# RL6955_IP_SVD register map
Vendor: Realtek
Registers are 32-bit, read-write, reset 0x0 unless marked. A register's access mark holds for its fields unless they carry their own. Offsets are from the block's base; [hi:lo] are bit positions; {n}, {i} and the like mark numbered series; <NAME> marks a mode.

## RMII_REG
Base 0x41800000
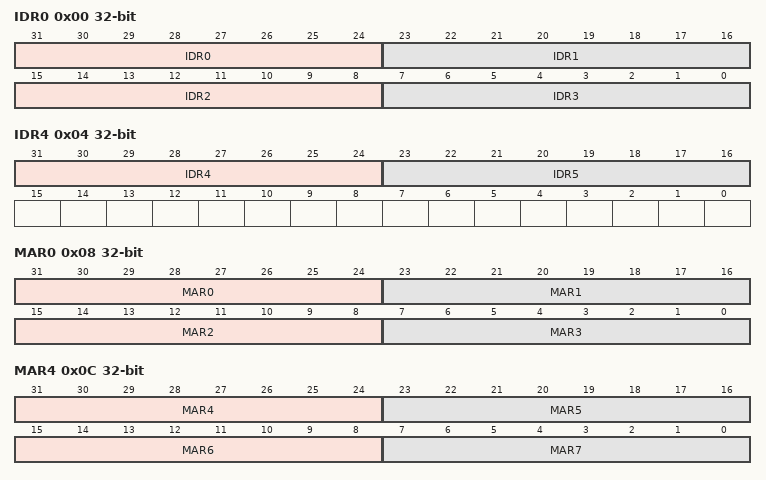
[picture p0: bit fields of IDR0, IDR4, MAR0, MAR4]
0x00 IDR0
  [31:24] IDR0 — The ID register0-5 are only permitted to write by 4-byte access. Read access can be byte, word, or double word access.
  [23:16] IDR1
  [15:8] IDR2
  [7:0] IDR3
0x04 IDR4
  [31:24] IDR4, [23:16] IDR5
0x08 MAR0
  [31:24] MAR0 — Multicast Register 0, The MAR register0-7 are only permitted to write by 4-byte access. Read access can be byte, word, or double word access. Driver is responsible for initializing these registers. The MAR7-0 define 64 bits which is a bit wise index of the multicast function of multicast addresses. The hash function of multicast address is the upper 6 MSB's of the CRC32 of the address (destination). The index then is the numerical representation of those 6 bits in hex format.
  [23:16] MAR1 — Multicast Register 1
  [15:8] MAR2 — Multicast Register 2
  [7:0] MAR3 — Multicast Register 3
0x0C MAR4
  [31:24] MAR4 — Multicast Register 4
  [23:16] MAR5 — Multicast Register 5
  [15:8] MAR6
  [7:0] MAR7 — Multicast Register 7
0x10 TxOKCNT 16-bit ro
  [15:0] TxOK — 16-bit counter of Tx Ok packets. Rolls over automatically. Write to clear.
0x12 RxOKCNT 16-bit ro
  [15:0] RxOk — 16-bit counter of Rx Ok packets. Rolls over automatically. Write to clear.
0x14 TxErr 16-bit ro
  [15:0] TxErr — 16-bit counter of TxErr packets. Rolls over automatically. Write to clear. The source of TxErr are txunder, txabt(in half-duplex mode) or txlinkerr.
0x16 RxErr 16-bit ro
  [15:0] RxErr — 16-bit counter of RxErr packets. Rolls over automatically. Write to clear. The source of RxErr are GMAC meets the following condition when rx fifo is not full.: 1. RCR.accept runt = 0, but the ingress pkt length < 64B. 2. RCR.accepterr = 0, but the ingress pkt is a CRC error pkt.
0x18 MissPkt 16-bit ro
  [15:0] MissPkt — 16-bit counter of Missed packets. Rolls over automatically. Write to clear.
0x1A FAE 16-bit ro
  [15:0] FAE — 16-bit counter of FAE (Frame Alignment Error) packets. Rolls over automatically. Write to clear. RCR.AER should be high. When FAE occurs in 10/100mode, the following thins happens: *Rx status des.CRC error does not assert if the ingress(exclude alignment error nibble) if correct. *RxErr_reg increased by 1. *FAE_reg increased by 1 *Rx status des.RCDF does not asserts. data length does not include alignment error nibble.
0x1C Tx1Col 16-bit ro
  [15:0] Tx1Col — 16-bit counter of TxCol packets. Rolls over automatically. Write to clear. This only record which have entered just one collision before Tx OK
0x1E TxMCol 16-bit ro
  [15:0] TxMCol — 16-bit counter of TxCol packets. Rolls over automatically. Write to clear. This keeps track of those packets with less than 16 collisions (or the configured retry count) before Tx Ok
0x20 RxOkPhy 16-bit ro
  [15:0] RxOkPhy — 16-bit counter of Rx Ok packets with physical address matching destination address. Rolls over automatically. Write to clear.
0x22 RxOkBrd 16-bit ro
  [15:0] RxOkBrd — 16-bit counter of Rx Ok packets with broadcast destination address.. Rolls over automatically. Write to clear.
0x24 RxOkMu1 16-bit ro
  [15:0] RxOkMul — 16-bit counter of Rx Ok packets with multicast destination address. Rolls over automatically. Write to clear.
0x26 TxAbt 16-bit ro
  [15:0] TxAbt — 16-bit counter of Tx aborted packets. Rolls over automatically. Write to clear. This accounts for over collision, underrun, LNK failure conditions.
0x28 TXUNDERC 16-bit ro
  [15:0] TXUNDERC — 16-bit counter of Tx Underrun packets. Rolls over automatically. Write to clear. gmac only.
0x2A Misspkt_rdu 16-bit ro
  [15:0] RDU_MISSPKTC — 16-bit counter of miss packets due to rx descriptor is unavailable. Rolls over automatically. Write to clear. gmac only.
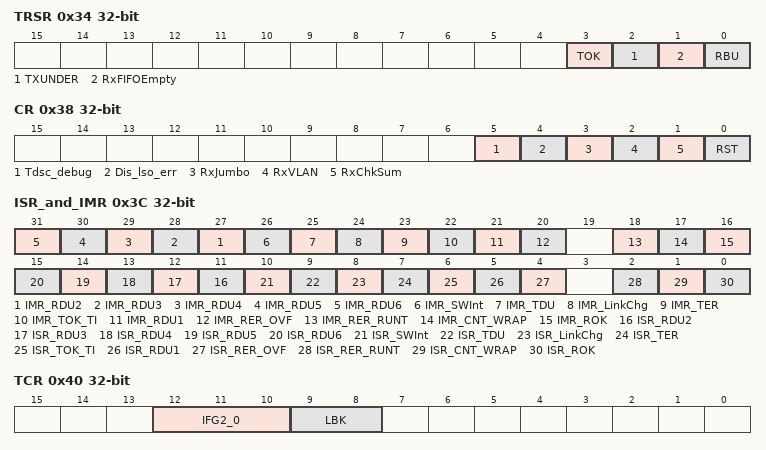
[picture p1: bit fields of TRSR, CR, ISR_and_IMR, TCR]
0x34 TRSR ro
  [3] TOK — Transmit OK: Set to 1 indicates that the transmission of a packet was completed successfully and no transmit underrun occurs.
  [2] TXUNDER — Transmit FIFO Underrun: Set to 1 if the Tx FIFO was exhausted during the transmission of a packet.
  [1] RxFIFOEmpty — Rx Fifo is Empty.
  [0] RBU — Rx buff is un-available, rx full
0x38 CR access per field
  [5] Tdsc_debug rw — Tx descriptor debug
  [4] Dis_lso_err rw — Disable LSO error
  [3] RxJumbo rw — 1: support jumbo packet receiving. The maximum packet size is 16384B(0x4000). 0: Does not support jumbo packet receiving. When rxjumbo sets to 1, the minium rx descriptor ring size is 16.
  [2] RxVLAN rw — Receive VLAN de-tagging enable.1: Enable. 0: Disable. 1: detag vlan and set rx status dsc.tava = 1 when ingress packet has vlantag. 0: disable detag vlan and rx status dsc.tava = 0.
  [1] RxChkSum rw — Receive checksum offload enable. 1: Enable. 0: Disable.
  [0] RST wo — Reset: Setting to 1 forces the Ethernet module to a software reset state which disables the transmitter and receiver, reinitializes the FIFOs, triggers interrupt Swint for RISC to reset the system buffer pointer to the initial value Tx/Rx FDP. The values of IDR0-5 and MAR0-7 will have no changes. This bit is 1 during the reset operation, and is cleared to 0 by the Ethernet Module when the reset operation is complete.
0x3C ISR_and_IMR access per field
  [n+25] IMR_RDU{n} rw (n=2..6)
  [26] IMR_SWInt rw
  [25] IMR_TDU rw
  [24] IMR_LinkChg rw
  [23] IMR_TER rw
  [22] IMR_TOK_TI rw
  [21] IMR_RDU1 rw
  [20] IMR_RER_OVF rw
  [18] IMR_RER_RUNT rw
  [17] IMR_CNT_WRAP rw
  [16] IMR_ROK rw
  [n+9] ISR_RDU{n} ro (n=2..6) — Rx Descriptor Unavailable for RING{n}: When set, indicates Rx descriptor is unavailable. Write 1 to clear.
  [10] ISR_SWInt ro — Software Interrupt pending: When set to 1 indicates a software interrupt was forced. Write 1 to clear.
  [9] ISR_TDU ro — Tx Descriptor Unavailable: When set, indicates Tx descriptor is unavailable. Write 1 to clear.
  [8] ISR_LinkChg ro — Link Change: Write 1 to clear.
  [7] ISR_TER ro — Transmit (Tx) Error: Indicates that a packet transmission was aborted, due to excessive collisions, according to the TXRR's setting. Write 1 to clear.
  [6] ISR_TOK_TI ro — Transmit Interrupt: Indicates that the DMA of the last descriptor of TxIntMitigation number of Tx packet has completed and the last descriptor has been closed. Write 1 to clear.
  [5] ISR_RDU1 ro — Rx Descriptor Unavailable for RING1: When set, indicates Rx descriptor is unavailable. Write 1 to clear.
  [4] ISR_RER_OVF ro — Rx FIFO Overflow, caused by RBO/RDU, poor system bus (Lexra bus) performance, or overloaded Lexra bus traffic. Write 1 to clear.
  [2] ISR_RER_RUNT ro — Rx error caused by runt error characterized by the frame length in bytes being less than 64 bytes. Write 1 to clear.
  [1] ISR_CNT_WRAP ro — Tx/rx counter wrap interrupt.
  [0] ISR_ROK ro — Receive (Rx) OK: This interrupt is set either when RxIntMitigation packet is met or RxPktTimer expires. Write 1 to clear.
0x40 TCR
  [12:10] IFG2_0 — InterFrameGap Time: This field allows the user to adjust the interframe gap time longer than the standard: 9.6 us for 10Mbps, 960 ns for 100Mbps. The time can be programmed from 9.6 us to 14.4 us (10Mbps) and 960ns to 1440ns (100Mbps). The formula for the inter frame gap is: IFG[2:0] IFG@1000MHz (nS) IFG@100MHz (nS) IFG@10MHz (uS) 0 1 1 96 960 9.6 1 0 0 96 +8 * 1 960 +8 * 10 9.6 +8 * 0.1 1 0 1 96 + 16 * 1 960 + 16 * 10 9.6 + 16 * 0.1 1 1 0 96 + 24 * 1 960 + 24 * 10 9.6 + 24 * 0.1 1 1 1 96 + 32 * 1 960 + 32 * 10 9.6 + 32 * 0.1 0 0 0 96 + 40 * 1 960 + 40 * 10 9.6 + 40 * 0.1 0 0 1 96 + 48 * 1 960 + 48 * 10 9.6 + 48 * 0.1 0 1 0 96 + 96 * 1 960 + 96 * 01 9.6 + 96 * 0.1
  [9:8] LBK — The loopback function must be independent of the link state. 2'b00 : normal operation 2'b01 : Loopback mode_R2T(lbkmode_r2t) : Lbk methld: no SW requirement. 1. receive ingress data. 2. assign rxd to txd (txd). 3. egress pkt. b10 : Reserved 2'b11 : Loopback mode(lbk_mode). Lbk method: 1. rx fet descriptor. 2. tx fet descriptor and data 3. put data in txfifo 4. assign txd to rxd.(lbk) 5. gmac mv data to lxb. In this mode(lbk_mode), the recommended value of RC_REG(0x44) is 0xf.
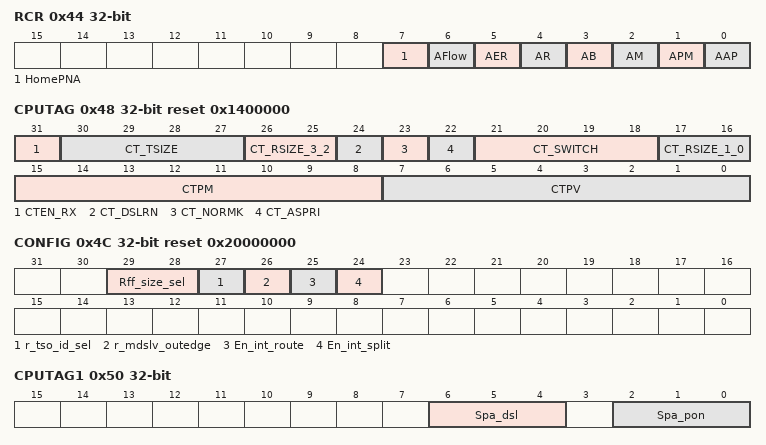
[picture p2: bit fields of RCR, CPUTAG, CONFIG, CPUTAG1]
0x44 RCR
  [7] HomePNA — Home PNA mode
  [6] AFlow — Accept flow control : When set to 1, flow control packet will also be received & DMA to rx buffer for debug. Default is 0.
  [5] AER — Accept Error Packet: When set to 1, all packets with CRC error, alignment error, and/or collided fragments will be accepted. Rxerrc keeps, Rxokc +1, Rx status dsc.CRC =1, Rx status dsc.RCDF =0. When set to 0, all packets with CRC error, alignment error, and/or collided fragments will be rejected. Rxerrc +1, Rxokc keeps, Rx status dsc.CRC =0, Rx status dsc.RCDF =1.
  [4] AR — Accept Runt: This bit allows the receiver to accept packets that are smaller than 64 bytes. The packet must be at least 8 bytes long to be accepted as a runt. Set to 1 to accept runt packets.
  [3] AB — Set to 1 to accept broadcast packets, 0 to reject.
  [2] AM — Set to 1 to accept multicast packets, 0 to reject. RC_REG.AB and AM should be enabled simulatanously.
  [1] APM — Set to 1 to accept physical match packets, 0 to reject.
  [0] AAP — Set to 1 to accept all packets with physical destination address, 0 to reject.
0x48 CPUTAG reset 0x1400000
  [31] CTEN_RX — Enable parsing ingress packet with cputag format.
  [30:27] CT_TSIZE — Cputag size in egress pkt. CTT_size: 4'h0: 0 Byte 4'h1: 4 Byte 4'h2: 8Byte 4'h3: 12 Byte
  [26:25] CT_RSIZE_3_2 — After rl8681 (including), this field is only for ingress pkt. CTR_size: 4'h0: 0 Byte 4'h1: 4 Byte 4'h2: 8Byte F or Apollo cputag with PTP timestamp, set CT_RSIZE to h2.
  [24] CT_DSLRN — In rtl8370s, Setting of Disable Learning field in tx cputag. Setting of Disable Learning field in RTL8368 or DSLRN field in RTL8307h tx cputag when short_dsc_format = 0.
  [23] CT_NORMK — Setting of NORMK field in RTL8307h tx cputag when short_dsc_format = 0.
  [22] CT_ASPRI — In RTL8307h, setting ASPRI field in tx cputag when short_dsc_format = 0. In RTL8370S, setting priority select field in tx cputag when short_dsc_format =0..
  [21:18] CT_SWITCH — Support cputag format of switch 0: no cputag support 1: 8368 2: 8306 3: 8307 4: 8370 5: gmac in 8681. 6: gmac in Apollo, rle0371, rl6266 and rtl9601(rle0639)
  [17:16] CT_RSIZE_1_0
  [15:8] CTPM — CPU tag protocol mask. 8306:0xf0 8368:0xe0 8370:0xff 8307h:0xff
  [7:0] CTPV — CPU tag protocol value. 8306:0x90 8368:0xa0 or 0xb0 8370:0x04 8307h:0x04
0x4C CONFIG reset 0x20000000
  [29:28] Rff_size_sel — Set gmac_rxfifo size. 2'b00: 1KB 2'b01: 1664B 2'b10: 2KB
  [27] r_tso_id_sel — 0: each ID of IP header is same as original ID. 1: increment 1 from original ID. Default value is 0.
  [26] r_mdslv_outedge — this bit works only in phy_mode 0: change mdio output data in falling edge 1: change mdio output data in rising edge
  [25] En_int_route — 0: disable interrupt routing, IMR0_reg, IMR1_reg. 1: enable interrupt routing, IMR0_reg, IMR1_reg.
  [24] En_int_split — When, en_int_route = 0, 0: only int.tdu, tok and rok present. 1: IMR0_reg, IMR1_reg and ISR1_reg present. When en_int_route = 1, this field is 1.
0x50 CPUTAG1
  [6:4] Spa_dsl
  [2:0] Spa_pon — The ingress cputag.SPA=PON field. Used in Apollo cputag.
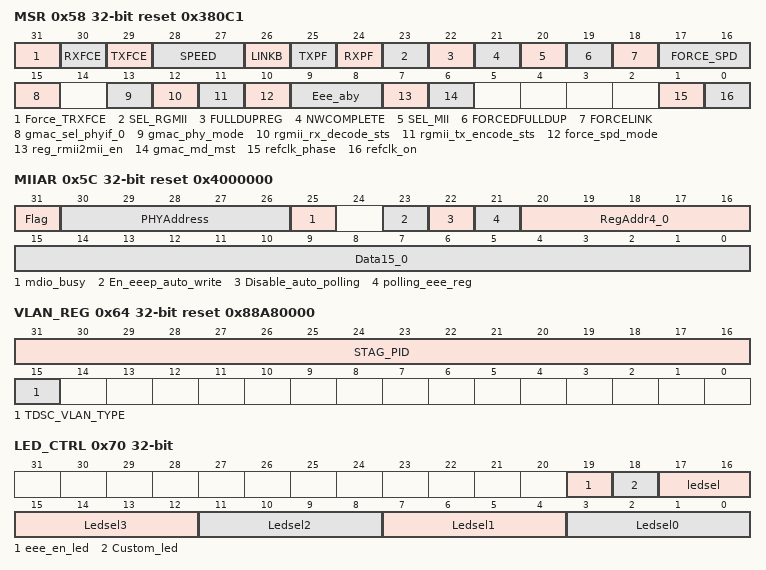
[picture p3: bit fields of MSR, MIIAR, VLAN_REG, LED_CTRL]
0x58 MSR access per field reset 0x380C1
  [31] Force_TRXFCE rw — Force Tx/RX Flow Control: 1 = enabled Flow control in the absence of NWAY. 0 = disables Flow control in the absence of NWAY. Version effect: rl6166(ECO) and after.
  [30] RXFCE rw — RX Flow control Enable: The flow control is enabled in full-duplex mode only. Packets are dropped if buffer is exhausted. Default is 0. 1 = Rx Flow Control Enabled. 0 = Rx Flow Control Disabled.
  [29] TXFCE rw — Tx Flow Control Enable: 1 = tx flow control enabled. 0 = tx flow control disabled. ACCEPT ERROR MUST NOT BE ENABLED
  [28:27] SPEED ro — {SPEED_1000, SPEED_10} 00: 100Mbps, 01: 10Mbps 10: 1000Mbps, 11: not allowed
  [26] LINKB ro — Inverse of Link status. 0 = Link OK. 1 = Link Fail.
  [25] TXPF ro — Tx Pause frame: 1 = Ethernet module has sent a pause packet. 0 = the Ethernet module has sent a timer done packet.
  [24] RXPF ro — Pause Flag: 1 = Ethernet module is in backoff state because a pause packet received. 0 = pause state is clear.
  [23] SEL_RGMII rw — gmac_sel_rgmii
  [22] FULLDUPREG ro — Indicates Full duplex mode from mdio results.
  [21] NWCOMPLETE ro — Nway complete
  [20] SEL_MII ro — indicates in mii mode.
  [19] FORCEDFULLDUP rw — force gmac operates at full duplex mode. This bit is Write only in RLE0315. This bit is R/W in RLE0390 (原RL6166). 1'b1: force gmac in full duplex mode. 1'b0: duplex status is from MDIO auto-polling. Not means gmac is in half duplex mode.
  [18] FORCELINK rw — force gmac in link ok mode. This bit is Write only in RLE0315. This bit is R/W in RLE0390 (RL6166). 1'b1: force gmac in linkok. 1'b0: link status is from MDIO auto-polling.
  [17:16] FORCE_SPD rw — Force gmac in 10/100/GIGA mode. 2'b00: 100M 2'b01: 10M 2'b10: GIGA 2'b11: not force mode. These bits are Write only in RLE0390 (RL6166). The current speed status of gmac can be checked in MSR_reg.{speed1000, speed_10}. In force mode, SW can set gmac operates in , FD and Link ok(for example) and SW can not set gmac operates in , HD and Link ok. When FORCEDFULLDUP is b0, the duplex status is from MDIO auto-polling, therefore, it is not controlled by SW.
  [15] gmac_sel_phyif_0 ro — 1: phy interface 0.works. 0: phy interface 1 works.
  [13] gmac_phy_mode rw — 1: in phy mode. (bit[6] will be read as '0') 0: not in phy mode. (bit[6] will be read as '1')
  [12] rgmii_rx_decode_sts rw — 0: Does not support rgmii in band status(link status, speed and duplex mode of the PHY) by decoding rxd. 1: Supports rgmii in band status(link status, speed and duplex mode of the PHY) by decoding rxd.
  [11] rgmii_tx_encode_sts rw — This field is valid only in phy mode. 0: Does not support rgmii in band status(link status, speed and duplex mode of the PHY) by encoding txd. 1: Supports rgmii in band status(link status, speed and duplex mode of the PHY) by encoding txd.
  [10] force_spd_mode rw — 1: gmac is in force speed mode. The real speed in force mode is set in MS_REG.FORCE_SPD. 0: gmac speed status is from md operation.
  [9:8] Eee_aby ro — Indicates eee ability of PCS. Eee_aby[0]: eee ability in 100M Eee_aby[1]: eee ability in giga mode.
  [7] reg_rmii2mii_en rw — 1: transfer MII signals to RMII signals This function is only valid in MII mode. (default 0: for AmebaI//AmebaPro/AmebaPro2)
  [6] gmac_md_mst ro — 1: GMAC is used to be MDIO master. (When bit[13] is setting as '0') 0: GMAC is used to be MDIO slave. (When bit[13] is setting as '1')
  [1] refclk_phase rw — 1: for Tx transaction, TXEN & TXD signals are changed on the falling edge of REF_CLK; for Rx transaction, RXD signals are sampled on the falling edge of REF_CLK 0: for Tx transaction, TXEN & TXD signals are changed on the rising edge of REF_CLK; for Rx transaction, RXD signals are sampled on the rising edge of REF_CLK
  [0] refclk_on rw — 1: REF_CLK on 0: REF_CLK off
0x5C MIIAR access per field reset 0x4000000
  [31] Flag rw — Flag bit, used to identify access to MII register: 1: Write data to MII register. Turns to 0 automatically upon completion of MAC writing to the specified MII register. 0: Read data from MII register. Turns to 1 automatically upon completion of MAC reading the specified MII register. Read write turn around time I s about 64 us.
  [30:26] PHYAddress rw — Defines the Phy address for the MII.
  [25] mdio_busy ro — MDIO is busy
  [23] En_eeep_auto_write rw — HW auto writes PCS.page4.reg20 and reg27 to adjust analog parameters based on eeep_lpi state. SW should change page to page4 then set MIIA_REG.en_eeep_auto_write. HW will write eeep_abig_on/off and eeep_ldvbias_on/off (in EEEP_CR6_REG and EEEP_CR7_REG) to PCS.page4.reg20 and reg27, respectively, based on eeep_lpi state. If SW wants to access another page of PCS, SW should disable MIIA_REG.en_eeep_auto_write.
  [22] Disable_auto_polling rw — Disable auto polling feature of mdio operation. 0: HW auto polling PCS status. 1: HW does not auto polling PCS status.
  [21] polling_eee_reg rw — polling PCS EEE advertisement register (7.60). In rl6166(原rle0315) and before: this bit is not supported. In rle0390: In in-direct method, gmac had to access PCS register by multiples R/W of reg13 and 14. It is OK for PCS to be aborted in the middle of indirect method. In rle0371: HW will complete current indirect access to PCS then stop in-direct method. Please refer to EEE_CR1_reg.
  [20:16] RegAddr4_0 rw — Defines 5-bit MII register address.
  [15:0] Data15_0 rw — Defines 16 bit MII resgister data.
0x60 SWINT wo
  [24] SWINT — Write 1 will force ISR register bit 10 set to 1
0x64 VLAN_REG reset 0x88A80000
  [31:16] STAG_PID — Set the s-tag protocol identifier. This field is valid only when COM_REG.TDSC_VLAN_TYPE is high.
  [15] TDSC_VLAN_TYPE — 1: tx command descriptor.tx_vlan_action is for s-tag. 0: tx command descriptor.tx_vlan_action is for c-tag.
0x70 LED_CTRL
  [19] eee_en_led — Enable/disable lpi led.
  [18] Custom_led — Custom led mode. 1: using custom led matrix table. 0: using Non-custom led table.
  [17:16] ledsel — Non custom led select. Following EEE spec, combine the Link signal and LPI signal in the same LED pin. While entering LPI state, LED will blink with 2784ms cycle, of which the first 2349ms LED light is turned off, after 435ms is turned on. NO EEE in RL6166.
  [4n+3:4n] Ledsel{n} (n=0..3) — Custom led{n} select.
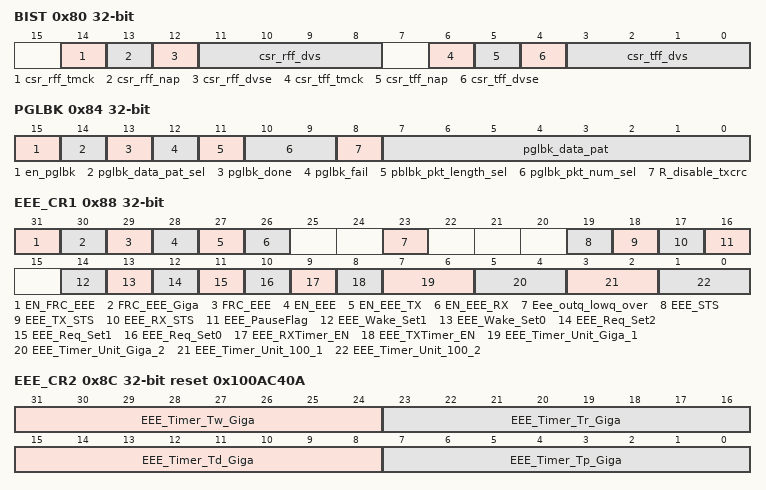
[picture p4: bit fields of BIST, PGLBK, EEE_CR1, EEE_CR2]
0x80 BIST
  [14] csr_rff_tmck — Set TMCK for RXFIFO
  [13] csr_rff_nap — Set NAP for RXFIFO
  [12] csr_rff_dvse — Set DVSE for RXFIFO
  [11:8] csr_rff_dvs — Set DVS for RXFIFO
  [6] csr_tff_tmck — Set TMCK for TXFIFO
  [5] csr_tff_nap — Set NAP for TXFIFO
  [4] csr_tff_dvse — Set DVSE for TXFIFO
  [3:0] csr_tff_dvs — Set DVS for TXFIFO
0x84 PGLBK access per field
  [15] en_pglbk rw — Enable packet generator mode
  [14] pglbk_data_pat_sel rw — 1: fixed pattern, 0: pseudo random
  [13] pglbk_done ro — packet generator in wire lbk mode status. 1: done
  [12] pglbk_fail ro — packet generator in wire lbk mode status. 1: fail
  [11] pblbk_pkt_length_sel rw — 0: random (range: 64-1504B), 1: 64B
  [10:9] pglbk_pkt_num_sel rw — 2'b00: 100 pkts, 2'b10: 5 pkts. 2'b01: 1 pkt 2'b11: reserved.
  [8] R_disable_txcrc rw — 1: not append CRC for egress packet. 0: append CRC for egress packet.
  [7:0] pglbk_data_pat rw — Pattern inside tx packet when pglbk_data_pat_sel is high. For RLE0516, only pglbk_data_pat[3:0] are used.
0x88 EEE_CR1 access per field
  [31] EN_FRC_EEE rw — Enable EEE force mode 0: Disable EEE FORCE Mode 1: Enable EEE FORCE Mode If EN_FRC_EEE=1, both FRC_EEE_Giga and FRC_EEE_100 are used to force MAC operation ability.
  [30] FRC_EEE_Giga rw — If EN_FRC_EEE=1, FRC_EEE_Giga: 0: Disable MAC EEE ability for 1000BASE-T. 1: Enable MAC EEE ability for 1000BASE-T. If EN_FRC_EEE=0, FRC_EEE_Giga means EEE advertisement register 7.60 bit[2]
  [29] FRC_EEE rw — If EN_FRC_EEE=1, FRC_EEE_100 0: Disable MAC EEE ability for 100BASE-TX. 1: Enable MAC EEE ability for 100BASE-TX. If EN_FRC_EEE=0, FRC_EEE_100 means EEE advertisement register 7.60 bit[1]
  [28] EN_EEE rw — Set same as PHY setting, for LED.
  [27] EN_EEE_TX rw — Enable MAC TX EEE ability 0: Disable EEE ability for TX. 1: Enable EEE ability for TX.
  [26] EN_EEE_RX rw — Enable MAC RX EEE ability 0: Disable EEE ability for RX. 1: Enable EEE ability for RX. Application note : The following methods could be used to disable EEE function. a) n[1:0] = 00 -> completely disable EEE function, or b) n[3:2] = 00 -> disable /1000Mbps EEE capability (excludes 10Mbps ).
  [23] Eee_outq_lowq_over rw — SW has many packets to be tranmitted, then set this bit to tell HW leave lpi state in condition2.
  [19] EEE_STS ro — Indicate EEE status, both TX and RX. 1: Both TX and RX in LPI mode simultaneously. 0: not both TX and RX in LPI mode simultaneously
  [18] EEE_TX_STS ro — Indicate EEE TX status 1: TX is in LPI mode. 0: TX is in normal mode.
  [17] EEE_RX_STS ro — Indicate Port 0 EEE RX status 1: RX is in LPI mode. 0: RX is in normal mode.
  [16] EEE_PauseFlag ro — Set indication for LPI request due to RX pause on frame. 1: indicate RX pause on frame; 0: no indicate.
  [14] EEE_Wake_Set1 rw — Enable LPI TX high priority pkt Wakeup decision maker for EEE. 1: enable; 0: disable. Gmac will leave lpi mode when EEE_CR1_reg.txq_th is met or one of the egress is larger than 512B.
  [13] EEE_Wake_Set0 rw — Enable LPI TX transmit wakeup decision maker for EEE. 1: enable; 0: disable.
  [12] EEE_Req_Set2 rw — Enable LPI TX request RX pause on frame decision maker for EEE. 1: enable; 0: disable.
  [11] EEE_Req_Set1 rw — Enable LPI TX request queue empty decision maker for EEE. 1: enable; 0: disable. For RLE0390(原RL6166), only for tx is single descriptor operation. For next version, this bit can support multi-descriptor operation.
  [10] EEE_Req_Set0 rw — Enable LPI TX request Rate decision maker for EEE. 1: enable; 0: disable.
  [9] EEE_RXTimer_EN rw — Enable RX meter to count RX LPI status time
  [8] EEE_TXTimer_EN rw — Enable TX meter to count TX LPI status time
  [7:6] EEE_Timer_Unit_Giga_1 rw — Set the unit for timer T_wakeup, T_tx_rate, and T_pause in EEE function. 00: 1uS; 01: 16 uS; 10: 128 uS; 11: 1024uS.
  [5:4] EEE_Timer_Unit_Giga_2 rw — Set the unit for timer T_tx_delay in EEE function. 00: 8uS; 01: 64uS; 10: 256uS; 11: 1024uS.
  [3:2] EEE_Timer_Unit_100_1 rw — Set the unit for timer T_wakeup, T_tx_rate, and T_pause in EEE function. 00: 1uS; 01: 16uS; 10: 128uS; 11: 1024uS.
  [1:0] EEE_Timer_Unit_100_2 rw — Set the unit for timer T_tx_delay in EEE function. 00: 8uS; 01: 64uS; 10: 512uS; 11: 1024uS.
0x8C EEE_CR2 reset 0x100AC40A
  [31:24] EEE_Timer_Tw_Giga — Timer value in EEE function for T_wakeup. Value from 0~256. Unit: EEE_Timer_Unit_Giga_1. Default value is 16 us.
  [23:16] EEE_Timer_Tr_Giga — Timer value in EEE function for T_tx_rate. Unit: EEE_Timer_Unit_Giga_1. Default value is 10 us.
  [15:8] EEE_Timer_Td_Giga — Timer value in EEE function for QoS based LPI decision maker T_tx_delay. Unit: EEE_Timer_Unit_Giga_2*4. Default value is 200 ms.
  [7:0] EEE_Timer_Tp_Giga — Timer value in EEE function for TX decision maker T_pause. Unit: EEE_Timer_Unit_Giga_1. Default value is 10 us.
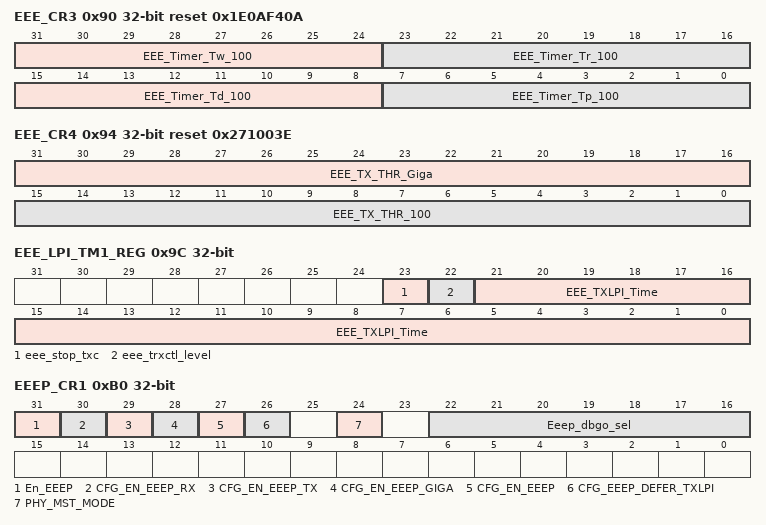
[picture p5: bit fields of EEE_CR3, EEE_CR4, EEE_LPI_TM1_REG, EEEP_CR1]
0x90 EEE_CR3 reset 0x1E0AF40A
  [31:24] EEE_Timer_Tw_100 — Timer value in EEE function for T_wakeup. Value from 0~256. Unit: EEE_Timer_Unit_100_1 Default value is 30 us.
  [23:16] EEE_Timer_Tr_100 — Timer value in EEE function for T_tx_rate. Unit: EEE_Timer_Unit_100_1. Default value is 10 us.
  [15:8] EEE_Timer_Td_100 — Timer value in EEE function for QoS based LPI decision maker T_tx_delay. Unit: EEE_Timer_Unit_100_2*4. Default value is 1s.
  [7:0] EEE_Timer_Tp_100 — Timer value in EEE function for TX decision maker T_pause. Unit: EEE_Timer_Unit_100_1. Default value is 10 us.
0x94 EEE_CR4 reset 0x271003E
  [31:16] EEE_TX_THR_Giga — Set the TX threshold in EEE function. Unit is Byte. EEE_TX_THR=Round [(T_tx_rate*Rate) / 8 ]. If you set T_tx_rate=10us, Rate=1000Mbps, so set EEE_TX_THR = 0x4E2 (1250bytes). Default value is 0x271(~half rate).
  [15:0] EEE_TX_THR_100 — Set the TX threshold in EEE function. Unit is Byte. EEE_TX_THR=Round [(T_tx_rate*Rate) / 8 ]. If you set T_tx_rate=10us, Rate=100Mbps, so set EEE_TX_THR = 0x7D (125bytes). Default value is 0x3E (~half rate).
0x98 EEE_LPI_TMO_REG ro
  [21:0] EEE_RXLPI_Time — RX in LPI time. (unit: 1us) (accumulation)Valid as (PORT_MASK[0]==1&&RXTimer_EN==1)
0x9C EEE_LPI_TM1_REG access per field
  [23] eee_stop_txc rw — This bit works in rgmii_1000 and rgmii_100 modes only. 1: gmac halts gmac_rgmii_txc_out when gmac enters lpi. 0: gmac does not halt gmac_rgmii_txc_out when gmac enters lpi. This bit should always be b0 for RLE0390(原RL6166). Gmac can halt gmac_rgmii_txc_out in the next version.
  [22] eee_trxctl_level rw — The gmac_rgmii_txe and gmac_rgmii_rxdv level when gmac is in lpi. 1: tx_ctl and rx_ctl is high when in lpi. 0: reserved.
  [21:0] EEE_TXLPI_Time ro — TX in LPI time. (unit: 1us ) (accumulation)Valid as (PORT_MASK[0]==1&&TXTimer_EN==1)
0xB0 EEEP_CR1
  [31] En_EEEP — Enable EEEP function 0b0: Disable EEEP function. 0b1: Enable EEEP function.
  [30] CFG_EN_EEEP_RX — 1: Enable EEEP RX. 0: Disable EEEP RX.
  [29] CFG_EN_EEEP_TX — 1: Enable EEEP TX. 0: Disable EEEP TX.
  [28] CFG_EN_EEEP_GIGA — 1: Enable EEEP in giga mode. 0: Disable EEEP in giga mode.
  [27] CFG_EN_EEEP — 1: Enable EEEP in mode. 0: Disable EEEP in mode.
  [26] CFG_EEEP_DEFER_TXLPI — ???
  [24] PHY_MST_MODE — When PMA is in master clock role, the EEEP_RX can work. SW needs to configure PCS reg9.bit12(Master-slave manual config enable) and reg9.bit11(Master-slave config value). Then setting EEEP_CR1_REG.PHY_MST_MODE.
  [22:16] Eeep_dbgo_sel — eeep module debug signals selection.
0xB4 EEEP_CR2 reset 0x1
  [7:0] EEEP_Sleep_Step — Value from 1 to 255, indicate the rx sleep step in EEEP function. Value 0 is the same as 1. EEPROM and register configurable.//???
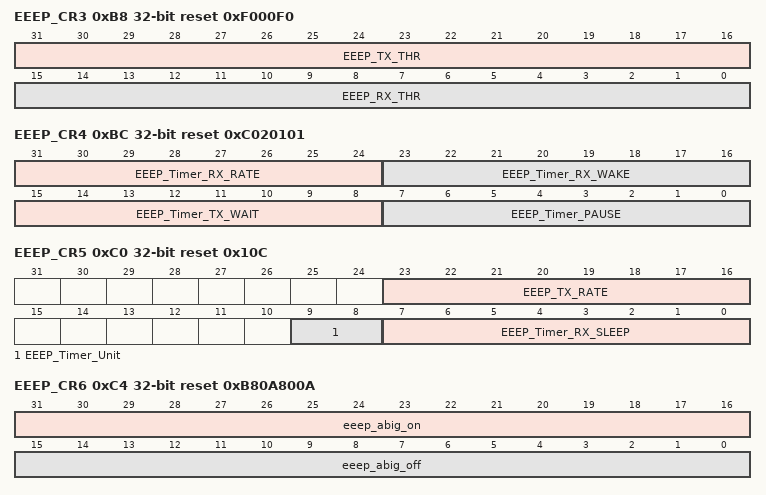
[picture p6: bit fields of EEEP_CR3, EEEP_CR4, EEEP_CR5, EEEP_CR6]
0xB8 EEEP_CR3 reset 0xF000F0
  [31:16] EEEP_TX_THR — Set the TX threshold in EEEP function. Unit: Byte; EEEP_TX_THR=Round [(T_rx_rate*Rate) / 8 ]. If you set T_rx_rate=192us,Rate=10Mbps, so set EEEP_TX_THR= 0xF0 (240 bytes). EEPROM and register configurable.//HYH???
  [15:0] EEEP_RX_THR — Set the RX threshold in EEEP function. Unit: Byte; EEEP_RX_THR=Round [(T_rx_rate*Rate) / 8 ]. If you set T_rx_rate=192us,Rate=10Mbps, so set EEEP_TX_THR= 0xF0 (240 bytes). EEPROM and register configurable. //HYH???
0xBC EEEP_CR4 reset 0xC020101
  [31:24] EEEP_Timer_RX_RATE — Timer value in EEEP function for T_rx_rate. Unit: microsecond. Default value is 192 us. EEPROM and register configurable.
  [23:16] EEEP_Timer_RX_WAKE — Timer value in EEEP function for T_rx_wake. Unit: microsecond. Default value is 32 us. EEPROM and register configurable.
  [15:8] EEEP_Timer_TX_WAIT — Timer value in EEEP function for T_tx_wait. Unit: microsecond. Default value is 16 us. EEPROM and register configurable.
  [7:0] EEEP_Timer_PAUSE — Timer value in EEEP function for T_pause_on. Unit:refer to EEEP_Timer_Unit. Default value is 16 us. EEPROM and register configurable.
0xC0 EEEP_CR5 reset 0x10C
  [23:16] EEEP_TX_RATE
  [9:8] EEEP_Timer_Unit — Set the unit for timer in EEEP function. 00: 1us; 01: 16us; 10: 128us; 11: 1024us. EEPROM and register configurable.
  [7:0] EEEP_Timer_RX_SLEEP — value of Timer in EEEP function for T_rx_sleep. Unit: microsecond. Default value is 192 us. EEPROM and register configurable.
0xC4 EEEP_CR6 reset 0xB80A800A
  [31:16] eeep_abig_on, [15:0] eeep_abig_off
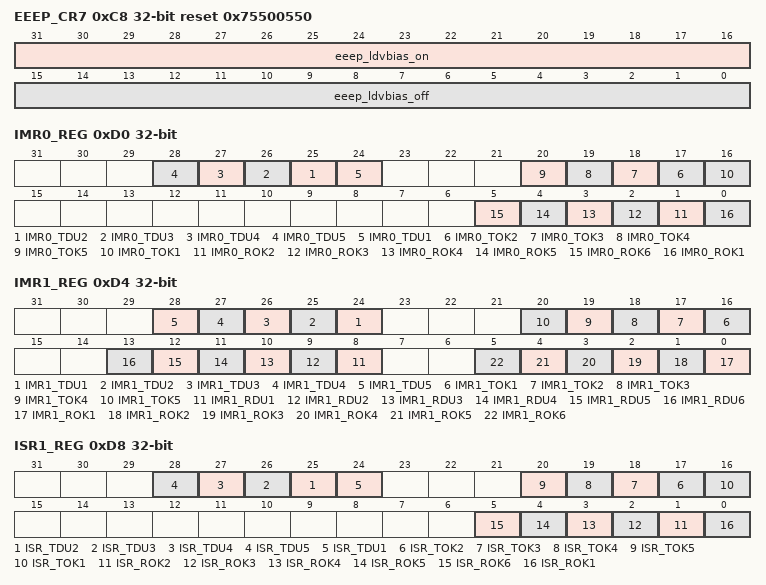
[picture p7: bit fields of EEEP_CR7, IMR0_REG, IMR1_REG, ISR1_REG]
0xC8 EEEP_CR7 reset 0x75500550
  [31:16] eeep_ldvbias_on, [15:0] eeep_ldvbias_off
0xD0 IMR0_REG access per field
  [n+23] IMR0_TDU{n} rw (n=2..5)
  [24] IMR0_TDU1 ro — This bit is IMR.tdu
  [n+15] IMR0_TOK{n} rw (n=2..5)
  [16] IMR0_TOK1 ro — This bit is IMR.tok
  [n-1] IMR0_ROK{n} rw (n=2..6)
  [0] IMR0_ROK1 ro — This bit is IMR.rok
0xD4 IMR1_REG
  [n+23] IMR1_TDU{n} (n=1..5), [n+15] IMR1_TOK{n} (n=1..5), [n+7] IMR1_RDU{n} (n=1..6), [n-1] IMR1_ROK{n} (n=1..6)
0xD8 ISR1_REG access per field
  [n+23] ISR_TDU{n} rw (n=2..5) — Tx Descriptor Ring{n} Unavailable: When set, indicates Tx descriptor Ring5 is unavailable. Write 1 to clear.
  [24] ISR_TDU1 ro — This bit is ISR.tdu
  [n+15] ISR_TOK{n} rw (n=2..5) — Transmit Interrupt: Indicates that the DMA of the last Ring{n} descriptor of TxIntMitigation number of Tx packet has completed and the last descriptor has been closed. Write 1 to clear.
  [16] ISR_TOK1 ro — This bit is ISR.tok
  [n-1] ISR_ROK{n} rw (n=2..6) — Receive (Rx) OK: This interrupt is set either when RxIntMitigation packet is met or RxPktTimer expires in Ring{n}. Write 1 to clear.
  [0] ISR_ROK1 ro — This bit is ISR.rok
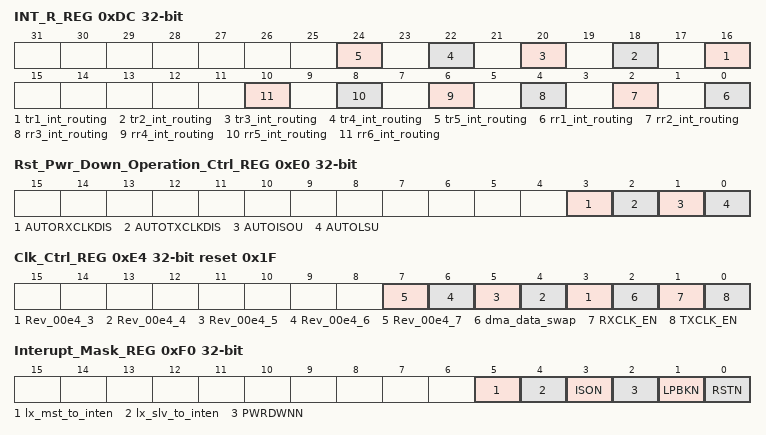
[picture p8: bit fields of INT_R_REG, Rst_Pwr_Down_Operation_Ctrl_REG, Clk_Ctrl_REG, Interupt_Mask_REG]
0xDC INT_R_REG
  [2n+14] tr{n}_int_routing (n=1..5), [2n-2] rr{n}_int_routing (n=1..6)
0xE0 Rst_Pwr_Down_Operation_Ctrl_REG
  [3] AUTORXCLKDIS — 1: Auto Disable Rx Clock when AUTOISOU=1
  [2] AUTOTXCLKDIS — 1: Auto Disable Tx Clock when AUTOISOU=1
  [1] AUTOISOU — Auto Isolate Update
  [0] AUTOLSU — Auto Link Status Update
0xE4 Clk_Ctrl_REG reset 0x1F
  [n] Rev_00e4_{n} (n=3..7) — Reserved bit
  [2] dma_data_swap — 1: Swap data order for dma_mst
  [1] RXCLK_EN — 0: Rx Clock Gated (txc_out)
  [0] TXCLK_EN — 0: Tx Clock Gated (rxc_out)
0xF0 Interupt_Mask_REG
  [5] lx_mst_to_inten — Interrupt enable of lexra master timeout
  [4] lx_slv_to_inten — Interrupt enable of lexra slave timeout
  [3] ISON — Isolate Notify
  [2] PWRDWNN — Power Down Notify
  [1] LPBKN — Loopback Notify
  [0] RSTN — Reset Notify
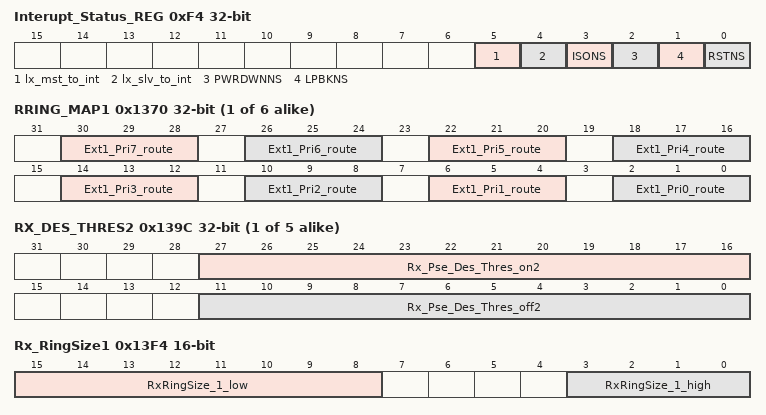
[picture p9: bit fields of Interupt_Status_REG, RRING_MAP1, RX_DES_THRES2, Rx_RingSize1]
0xF4 Interupt_Status_REG access per field
  [5] lx_mst_to_int rw — Interrupt status of lexra master timeout
  [4] lx_slv_to_int rw — Interrupt status of lexra slave timeout
  [3] ISONS ro — Isolate Notify When set, indicate Isolate is detected. Write 1 to clear.
  [2] PWRDWNNS ro — Power Down Notify When set, indicate Isolate is detected. Write 1 to clear.
  [1] LPBKNS ro — Loopback Notify When set, indicate Isolate is detected. Write 1 to clear.
  [0] RSTNS ro — Reset Notify When set, indicate Isolate is detected. Write 1 to clear.
{0x12F0+0x10*i} TxFDP{i} (i=1..5)
  [31:2] TxFDP{i} — Tx {i}st priority Descriptor Pointer to the Tx Ring
{0x12F4+0x10*i} TxCDO{i} ro (i=1..5)
  [11:0] TxCDO{i} — Tx {i}st priority Current Descriptor Offset: FDP+CDO = current descriptor pointer. CDO increments by 16 bytes each time.
{0x136C+4i} RRING_MAP{i} (i=1..6)
  [30:28] Ext{i}_Pri7_route — Cputag.priority = 7 route select. {0,1,7} ring1, {2} ring2, {3} ring3,...
  [26:24] Ext{i}_Pri6_route — Cputag.priority = 6 route select. {0,1,7} ring1, {2} ring2, {3} ring3,...
  [22:20] Ext{i}_Pri5_route — Cputag.priority = 5 route select. {0,1,7} ring1, {2} ring2, {3} ring3,...
  [18:16] Ext{i}_Pri4_route — Cputag.priority = 4 route select. {0,1,7} ring1, {2} ring2, {3} ring3,...
  [14:12] Ext{i}_Pri3_route — Cputag.priority = 3 route select. {0,1,7} ring1, {2} ring2, {3} ring3,...
  [10:8] Ext{i}_Pri2_route — Cputag.priority = 2 route select. {0,1,7} ring1, {2} ring2, {3} ring3,...
  [6:4] Ext{i}_Pri1_route — Cputag.priority = 1 route select. {0,1,7} ring1, {2} ring2, {3} ring3,...
  [2:0] Ext{i}_Pri0_route — Cputag.priority = 0 route select. {0,1,7} ring1, {2} ring2, {3} ring3,...
{0x1370+0x10*i} RxFDP{i} (i=2..6)
  [31:2] RxFDP{i} — Rx queue Descriptor Pointer to the Rx Ring
{0x1374+0x10*i} RxRingSize{i} 16-bit (i=2..6)
  [11:0] RxRingSize{i} — The total number of descriptors in the Rx descriptor rings of queue. Act as bit mask, eg. RxRingSize [11:0]: 0000_0000_1111: 16 descriptors 0000_0001_1111: 32 descriptors 0000_0011_1111: 64 descriptors 0000_0111_1111: 128 descriptors 0000_1111_1111: 256 descriptors 0001_1111_1111: 512 descriptors 0011_1111_1111: 1024 descriptors 0111_1111_1111: 2048 descriptors 1111_1111_1111: 4096 descriptors Any other value in this register yields undefined results.
{0x1376+0x10*i} RxCDO{i} 16-bit ro (i=2..6)
  [11:0] RxCDO{i} — Rx Current Descriptor Offset of queue: RxFDP+RxCDO = current descriptor pointer. CDO increments by 16 each time (each increment is one byte)
{0x1378+0x10*i} RX_CPU_DESN{i} (i=2..6)
  [11:0] EthrntRxCPU_Des_Num{i} — Indicate the number of descriptor of queue, which has been finished Rx process and returned to IO by CPU. After ending Rx process, CPU needs to update this field.
{0x137C+0x10*i} RX_DES_THRES{i} (i=2..6)
  [27:16] Rx_Pse_Des_Thres_on{i} — Specifies the difference between EthrnetRxCPU_Des_Num2 and the descriptor of queue currently in use by Ethernet Module in which flow control will be assert.
  [11:0] Rx_Pse_Des_Thres_off{i} — Specifies the difference between EthrnetRxCPU_Des_Num2 and the descriptor of queue currently in use by Ethernet Module in which flow control will be de-assert. Rx_Pse_Des_Thress_off_ should be less than (EthrntRxCPU_DES_NUM_ - X). X is the maximum rx descriptors will be used for single ingress packet.
0x13F0 Rx_FDP1
  [31:2] RxFDP1 — Rx 1st queue Descriptor Pointer to the Rx Ring
0x13F4 Rx_RingSize1 16-bit
  [15:8] RxRingSize_1_low — This is the total number of descriptors in the Rx descriptor rings of 1st queue. Act as bit mask, eg. RxRingSize [11:0]: 0000_0000_1111: 16 descriptors 0000_0001_1111: 32 descriptors 0000_0011_1111: 64 descriptors 0000_0111_1111: 128 descriptors 0000_1111_1111: 256 descriptors 0001_1111_1111: 512 descriptors 0011_1111_1111: 1024 descriptors 0111_1111_1111: 2048 descriptors 1111_1111_1111: 4096 descriptors Any other value in this register yields undefined results.
  [3:0] RxRingSize_1_high — This is the bits11-8 of RxRingSize1.
0x13F6 Rx_CDO1 16-bit ro
  [11:0] RxCDO1 — Rx Current Descriptor Offset of 1st queue: RxFDP+RxCDO = current descriptor pointer. CDO increments by 16 each time (each increment is one byte).
0x13FC SMSA
  [31:0] SMSA — SRAM mapping start address for header mapping to sram
0x1400 Probe_selexct
  [3:0] Probe_signal_select — For debug port signals use Value = 4: Tx/Rx related signals
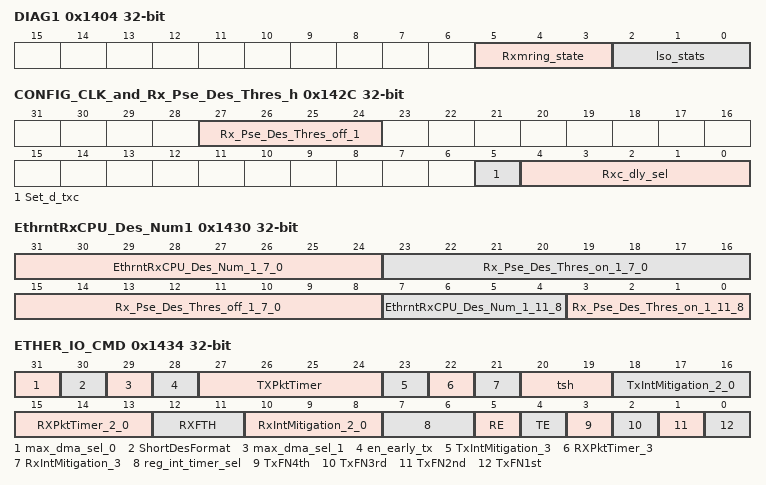
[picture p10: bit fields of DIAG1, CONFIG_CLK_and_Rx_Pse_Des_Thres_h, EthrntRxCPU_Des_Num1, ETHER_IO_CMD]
0x1404 DIAG1 ro
  [5:3] Rxmring_state
  [2:0] lso_stats — Reserved(3bits)
0x142C CONFIG_CLK_and_Rx_Pse_Des_Thres_h
  [27:24] Rx_Pse_Des_Thres_off_1 — This is the Rx_Pse_Des_Thres_off1[11:8].
  [5] Set_d_txc — Add delay to gmii_txc_out. Used in clk. Rgmii_1000: add 2nS delay. Rgmii_100: add 4nS delay. Rgmii_10: add 4nS delay.
  [4:0] Rxc_dly_sel — 32-tap delay chain for rxc. This field is valid when CONFIG_CLK_REG.dis_dly_mode is 0.
0x1430 EthrntRxCPU_Des_Num1
  [31:24] EthrntRxCPU_Des_Num_1_7_0 — Indicate the number of descriptor of 1st queue, which has been finished Rx process and returned to IO by CPU. After ending Rx process, CPU needs to update this field.
  [23:16] Rx_Pse_Des_Thres_on_1_7_0 — Specifies the difference between EthrnetRxCPU_Des_Num1 and the descriptor of 1st queue currently in use by Ethernet Module in which flow control will be assert.
  [15:8] Rx_Pse_Des_Thres_off_1_7_0 — Specifies the difference between EthrnetRxCPU_Des_Num1 and the descriptor of 1st queue currently in use by Ethernet Module in which flow control will be de-assert. Rx_Pse_Des_Thress_off_1 should be less than (EthrntRxCPU_DES_NUM_1 - X). X is the maximum rx descriptors will be used for single ingress packet.
  [7:4] EthrntRxCPU_Des_Num_1_11_8 — This is the EthrntRxCPU_Des_Num1[11:8].
  [3:0] Rx_Pse_Des_Thres_on_1_11_8 — This is the Rx_Pse_Des_Thres_on1[11:8].
0x1434 ETHER_IO_CMD access per field
  [31] max_dma_sel_0 rw — Select the dma burst size on bus(memory controller should assert continuous btrdy). 00:16 DW(1DW=4B) 01:32 DW 10:64 DW 11:128DW. AmebaI/AmebaPro/AmebaPro2 only support DMA burst length = 16DW
  [30] ShortDesFormat rw — Short descriptor format. Set 1 tx/rx descriptor will use old format - 4x32bit each item, set 0 use new format to support sram mapping AmebaI/AmebaPro/AmebaPro2 only support old format (1b'1)
  [29] max_dma_sel_1 rw — see Ethernet_IO_CMD.bit31 AmebaI/AmebaPro/AmebaPro2 only support DMA burst length = 16DW
  [28] en_early_tx rw — default 0, 0: disable, 1: enable. Disable early tx by GAMC while tx command descriptor.IPCS, UDPCS or TCPCS are set to high. For multiple tx descriptor application, this field should be 0. For low lxbus throughput environment, this field should be 0. For slow clk_gmac application, this field should be 0.
  [27:24] TXPktTimer rw — Timer to trigger TxOK interrupt before receipt of TxIntMitigation pkts. 0000 - no timer set 0001 ~ 1111 : the timer interval defining a multiple of TU ex: 0011 = timer interval set to 3 x4 =12TU Once TxOK is asserted the timer mechanism is reinitialized.
  [23] TxIntMitigation_3 rw — see Ethernet_IO_CMD.bit18-16
  [22] RXPktTimer_3 rw — see Ethernet_IO_CMD.bit15-13
  [21] RxIntMitigation_3 rw — see Ethernet_IO_CMD.bit10-8
  [20:19] tsh rw — Tx Threshold: Specifies the threshold level in the Tx FIFO to begin the transmission. When the byte count of the data in the Tx FIFO reaches this level, (or the FIFO contains at least one complete packet or the end of a packet) the Ethernet module will transmit this packet. 00:128B. 01:256B. 10:512B. 11:1024B. For poor lxbus bandwidth, tsh should be set b11. In rle0516, this field should be setted 0 or 1 (128B).
  [18:16] TxIntMitigation_2_0 rw — This sets the number of packets received before TxOK interrupt is triggered. 0000- 1 pkt 0001- 4 pkts 0010- 8 pkts 0011- 12 pkts 0100- 16 pkts 0101- 20 pkts 0110- 24 pkts 0111- 28 pkts ...
  [15:13] RXPktTimer_2_0 rw — Timer to trigger RxOK interrupt before receipt of RxIntMitigation pkts. 0000 - no timer set 0001 ~ 1111 : the timer interval defining a multiple of TU ex: 011 = timer interval set to 3 x4 =12TU This only applies to packets of size larger than 128 bytes. Once RxOK is asserted the timer mechanism is reinitialized. For ingress pkt which is short than 128B, RxOK interrupt asserts after DMA completes.
  [12:11] RXFTH rw — Rx Threshold: Specifies the threshold level in the Rx FIFO to begin the transmission. When the byte count of the data in the Rx FIFO reaches this level, (or the FIFO contains at least one complete packet or the end of a packet) the Ethernet module will transmit this packet. 00: 1024B 01: 128B 10: 256B 11: 512B The rx threshold should be larger than maximum dma burst size. The combination of max_dma_sel and rxfth are listed as followed: max_dma_sel rxfth b00(64B) b00(1024B), b01 (128B), b10(256B), b11(512B). b01(128B) b00(1024B), b10(256B), b11(512B). b10(256B) b00(1024B), b11(512B), In rle0516: SW should not set rxfth to 0b00 due to the rx fifo size is only 512B. The recommend value of rle0516 is 0b11 for performance concerns. 00 = no rx threshold. The Ethernet Module begins the transfer of data after having received a whole packet in the FIFO. 01 = 32 bytes 10 = 64 bytes 11 = 128 bytes max_dma_sel rxfth b0(64B) b10(64B), b11(128B). b1(128B) b11(128B).
  [10:8] RxIntMitigation_2_0 rw — This sets the number of packets received before RxOK interrupt is triggered. 0000- 1 pkt 0001- 4 pkts 0010- 8 pkts 0011- 12pkts 0100- 16 pkts 0101- 20 pkts 0110- 24 pkts 0111- 28 pkts ...
  [7:6] reg_int_timer_sel rw — RXPktTimer, TXPktTimer Unit. (TU) speed TU 00: 10M 25.6uS 00: 100M 2.56uS 00: 1000M 256nS 01: 10M 102.4uS 01: 100M 10.24uS 01: 1000M 1.024uS 10: 10M 409.6uS 10: 100M 40.96uS 10: 1000M 4.096uS 11: 10M 1.6mS 11: 100M 0.16mS 11: 1000M 16uS
  [5] RE rw — MII Rx Enable
  [4] TE rw — MII Tx Enable
  [3] TxFN4th wo — 4th Priority DMA-Ethernet Transmit enable. 1: Enable. 0: Disable.
  [2] TxFN3rd wo — 3rd Priority DMA-Ethernet Transmit enable. 1: Enable. 0: Disable.
  [1] TxFN2nd wo — 2nd Priority DMA-Ethernet Transmit enable. 1: Enable. 0: Disable.
  [0] TxFN1st wo — 1st Priority DMA-Ethernet Transmit enable. 1: Enable. 0: Disable.
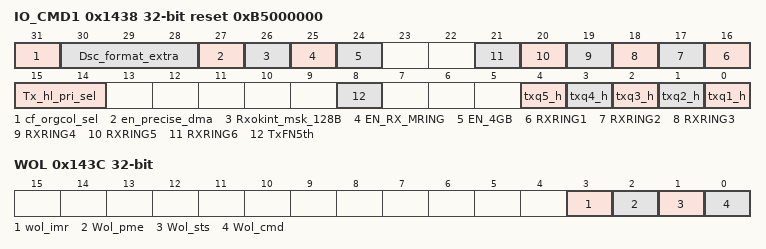
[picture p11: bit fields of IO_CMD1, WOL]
0x1438 IO_CMD1 access per field reset 0xB5000000
  [31] cf_orgcol_sel rw — 0: using GMAC internal generated collision signal 1: using MII interface collision signal( (default 1: AmebaPro2)
  [30:28] Dsc_format_extra rw — Extra descriptor format. In rle0437, bit28 is is write only. SW should set this field before set IO_CMD.TE or RE to 1. AmebaI/AmebaPro/AmebaPro 2 only support the fixed value 3b'011
  [27] en_precise_dma rw — 0: disable precise DMA transfer. 1: enable precise DMA transfer. AmebaI/AmebaPro/AmebaPro2 only support 1b'0 (disable precise DMA transfer)
  [26] Rxokint_msk_128B rw — 1: For ingress pkt which is short than 128B, RxOK interrupt asserts after DMA completes (compatible issue). 0: For ingress pkt which is short than 128B, RxOK interrupt does not assert after DMA completes.
  [25] EN_RX_MRING rw — Enable rx multiple rings. 1: rx using multiple rings. max: 6rings (ring1 to ring6). 0 rx using single ring (ring1 only). SW should set this field before set IO_CMD.TE or RE to 1 AmebaI/AmebaPro/AmebaPro2 only support single rx ring
  [24] EN_4GB rw — 1: support 4GB addressing in lx master bus. For gmac used in rl0371 and after. 0: no support. For project used in rle0390 and before. SW should set this field before set IO_CMD.TE or RE to 1 AmebaPro2 support 4GB addressing AmebaI/AmebaPro only support 1GB addressing
  [n+15] RXRING{n} wo (n=1..6) — Ethernet-DMA Receive Ring{n} enable. 1: Enable. 0: Disable. If RXRING{n} is not used, SW should put one dummy rx command descriptor (own = 0) at RXFDP{n}_reg.
  [15:14] Tx_hl_pri_sel rw — b00: TX ring uses strict priority. b01: TX ring uses high and low queue priority. Inside high queue, tx ring is round robin. Inside low queue, tx ring is round robin. Strict priority is used for high and low queue selection. b10 and b11: reserved. In RL6266, when tx_hl_pri is 1, txq1_h and txq2_h are 1 and txq3_h, txq4_h and txq5_h are 0. SW should set this field before set IO_CMD.TE to 1. AmebaI/AmebaPro/AmebaPro2 only support the fixed value 2b'00
  [8] TxFN5th wo — 5th Priority DMA-Ethernet Transmit enable. 1: Enable. 0: Disable. After IO_CMD.TE is set high, TxFN5th is writable.
  [4] txq5_h rw — 1: TxFN5th is a high queue. 0: TxFN5th is a low queue. This field is only used in eee.
  [3] txq4_h rw — 1: TxFN4th is a high queue. 0: TxFN4th is a low queue. This field is only used in eee.
  [2] txq3_h rw — 1: TxFN3rd is a high queue. 0: TxFN3rd is a low queue. This field is only used in eee.
  [1] txq2_h rw — 1: TxFN2nd is a high queue. 0: TxFN2nd is a low queue. This field is only used in eee.
  [0] txq1_h rw — 1: TxFN1st is a high queue. 0: TxFN1st is a low queue. This field is only used in eee.
0x143C WOL access per field
  [3] wol_imr rw — Interrupt mask of wol_pme.
  [2] Wol_pme ro — HW asserts pme when a.HW entered wol idle state and b.received magic ingress pkt. HW asserts pme to wake up system. Wol_pme indicates: 0: No magic pkt receives. 1: HW had received one magic pkt and system should wake up.
  [1] Wol_sts ro — HW enters wol idle state when a. SW issues wol_cmd state and b. HW tx/rx function enter idle state. Wol_sts indicates: 0: HW is not in wol idle state. 1: HW is in wol idle state.
  [0] Wol_cmd rw — Issue wol command by SW
